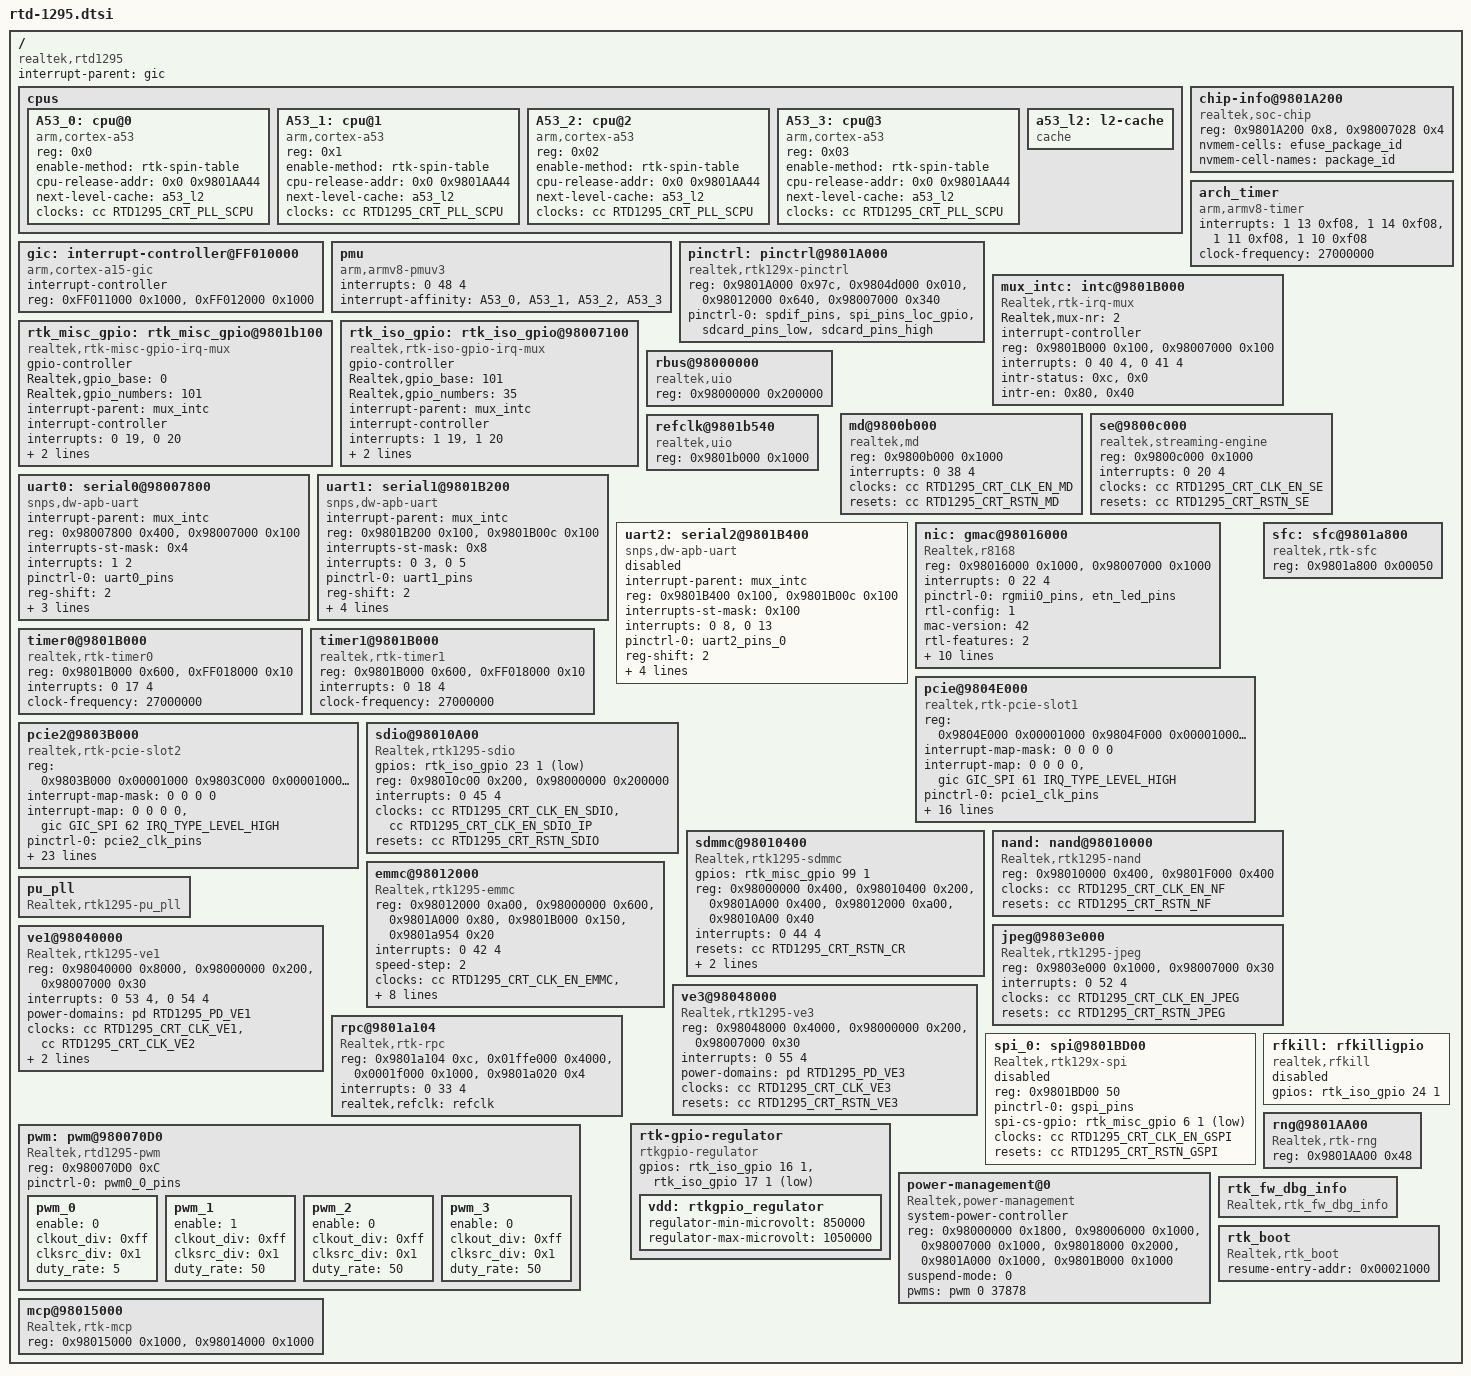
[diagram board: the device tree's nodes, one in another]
#include <dt-bindings/interrupt-controller/irq.h>
#include <dt-bindings/interrupt-controller/arm-gic.h>
#include "rtd-129x.dtsi"
/include/ "rtd-1295-pinctrl.dtsi"
/include/ "rtd-1295-usb.dtsi"
#include  "rtd-1295-sata.dtsi"
/include/ "rtd-129x-dcsys-debug.dtsi"

/{
	compatible = "realtek,rtd1295";
	interrupt-parent = <&gic>;
	#address-cells = <1>;
	#size-cells = <1>;

	cpus {
		#address-cells = <1>;
		#size-cells = <0>;

		A53_0: cpu@0 {
			device_type = "cpu";
			compatible = "arm,cortex-a53", "arm,armv8";
			reg = <0x0>;
			enable-method = "rtk-spin-table";
			cpu-release-addr = <0x0 0x9801AA44>;
			next-level-cache = <&a53_l2>;
			clocks = <&cc RTD1295_CRT_PLL_SCPU>;
			#cooling-cells = <2>;
		};

		A53_1: cpu@1 {
			device_type = "cpu";
			compatible = "arm,cortex-a53", "arm,armv8";
			reg = <0x1>;
			enable-method = "rtk-spin-table";
			cpu-release-addr = <0x0 0x9801AA44>;
			next-level-cache = <&a53_l2>;
			clocks = <&cc RTD1295_CRT_PLL_SCPU>;
			#cooling-cells = <2>;
		};

		A53_2: cpu@2 {
			device_type = "cpu";
			compatible = "arm,cortex-a53", "arm,armv8";
			reg = <0x02>;
			enable-method = "rtk-spin-table";
			cpu-release-addr = <0x0 0x9801AA44>;
			next-level-cache = <&a53_l2>;
			clocks = <&cc RTD1295_CRT_PLL_SCPU>;
			#cooling-cells = <2>;
		};

		A53_3: cpu@3 {
			device_type = "cpu";
			compatible = "arm,cortex-a53", "arm,armv8";
			reg = <0x03>;
			enable-method = "rtk-spin-table";
			cpu-release-addr = <0x0 0x9801AA44>;
			next-level-cache = <&a53_l2>;
			clocks = <&cc RTD1295_CRT_PLL_SCPU>;
			#cooling-cells = <2>;
		};

		a53_l2: l2-cache {
			compatible = "cache";
		};
	};

	chip-info@9801A200 {
		compatible = "realtek,soc-chip";
		reg = <0x9801A200 0x8>,
			<0x98007028 0x4>;
		nvmem-cells = <&efuse_package_id>;
		nvmem-cell-names = "package_id";
	};

	arch_timer {
		compatible = "arm,armv8-timer";
		interrupts = <1 13 0xf08>,
			<1 14 0xf08>,
			<1 11 0xf08>,
			<1 10 0xf08>;
		clock-frequency = <27000000>;
	};

	gic: interrupt-controller@FF010000 {
		compatible = "arm,cortex-a15-gic";
		#interrupt-cells = <3>;
		interrupt-controller;
		reg = <0xFF011000 0x1000>,
			<0xFF012000 0x1000>;
	};

	pmu {
		compatible = "arm,armv8-pmuv3";
		interrupts = <0 48 4>;
		interrupt-affinity = <&A53_0>,
			<&A53_1>,
			<&A53_2>,
			<&A53_3>;
	};

	pinctrl: pinctrl@9801A000 {
		compatible = "realtek,rtk129x-pinctrl";
		reg = <0x9801A000 0x97c>,
			<0x9804d000 0x010>,
			<0x98012000 0x640>,
			<0x98007000 0x340>;
		#gpio-range-cells = <3>;
		pinctrl-names = "default";
		pinctrl-0 =
			<&spdif_pins>,
			<&spi_pins_loc_gpio>,
			<&sdcard_pins_low>,
			<&sdcard_pins_high>;
		status = "okay";
	};

	mux_intc: intc@9801B000 {
		compatible = "Realtek,rtk-irq-mux";
		Realtek,mux-nr = <2>;
		#interrupt-cells = <2>;
		interrupt-controller;
		reg = <0x9801B000 0x100>, /* MISC_TOP MISC_ISO */
			<0x98007000 0x100>;
		interrupts = <0 40 4>, <0 41 4>;
		intr-status = <0xc>, <0x0>;
		intr-en = <0x80>, <0x40>;
		status = "okay";
	};

	rtk_misc_gpio: rtk_misc_gpio@9801b100 {
		compatible = "realtek,rtk-misc-gpio-irq-mux";
		gpio-controller;
		#gpio-cells = <3>; /*must be the same with gpiochip.of_gpio_n_cells*/
		Realtek,gpio_base = <0>;
		Realtek,gpio_numbers = <101>;
		interrupt-parent = <&mux_intc>;
		#interrupt-cells = <1>;
		interrupt-controller;
		interrupts = <0 19>, <0 20>; /*GPIOA_INT   GPIODA_INT*/
		reg = <0x9801b000 0x100>,
			<0x9801b100 0x100>; /* MISC_SYS MISC_GPIO*/
		gpio-ranges = <&pinctrl 0 0 101>;
		status = "okay";
	};

	rtk_iso_gpio: rtk_iso_gpio@98007100 {
		compatible = "realtek,rtk-iso-gpio-irq-mux";
		gpio-controller;
		#gpio-cells = <3>;
		Realtek,gpio_base = <101>;
		Realtek,gpio_numbers = <35>;
		interrupt-parent = <&mux_intc>;
		#interrupt-cells = <1>;
		interrupt-controller;
		interrupts = <1 19>, <1 20>; /*GPIOA_INT   GPIODA_INT*/
		reg = <0x98007000 0x100>,
			<0x98007100 0x100>; /* ISO_SYS ISO_GPIO*/
		gpio-ranges = <&pinctrl 0 101 35>;
		status = "okay";
	};

	rbus@98000000 {
		compatible = "realtek,uio";
		reg = <0x98000000 0x200000>;
		status = "okay";
	};

	md@9800b000 {
		compatible = "realtek,md";
		reg = <0x9800b000 0x1000>;
		interrupts = <0 38 4>; /* 70 - 32 = 38 */
		clocks = <&cc RTD1295_CRT_CLK_EN_MD>;
		resets = <&cc RTD1295_CRT_RSTN_MD>;
		status = "okay";
	};

	se@9800c000 {
		compatible = "realtek,streaming-engine";
		reg = <0x9800c000 0x1000>;
		interrupts = <0 20 4>; /* 52 - 32 = 20 */
		clocks = <&cc RTD1295_CRT_CLK_EN_SE>;
		resets = <&cc RTD1295_CRT_RSTN_SE>;
		status = "okay";
	};

	refclk@9801b540 {
		compatible = "realtek,uio";
		reg = <0x9801b000 0x1000>;
		status = "okay";
	};

	uart0: serial0@98007800 {
		compatible = "snps,dw-apb-uart";
		interrupt-parent = <&mux_intc>;
		reg = <0x98007800 0x400>,
			<0x98007000 0x100>;
		interrupts-st-mask = <0x4>;
		interrupts = <1 2>;
		pinctrl-names = "default";
		pinctrl-0 = <&uart0_pins>;
		reg-shift = <2>;
		reg-io-width = <4>;
		clock-names = "apb_pclk";
		clocks = <&ic RTD1295_ISO_CLK_EN_UR0>;
		clock-frequency = <27000000>; /* This value must be override by the board. */
		status = "okay";
	};

	uart1: serial1@9801B200 {
		compatible = "snps,dw-apb-uart";
		interrupt-parent = <&mux_intc>;
		reg = <0x9801B200 0x100>,
			<0x9801B00c 0x100>;
		interrupts-st-mask = <0x8>;
		interrupts = <0 3>, <0 5>; /*UR1_INT and UR1_TO_INT*/
		pinctrl-names = "default";
		pinctrl-0 = <&uart1_pins>;
		reg-shift = <2>;
		reg-io-width = <4>;
		clock-names = "apb_pclk";
		clocks = <&cc RTD1295_CRT_CLK_EN_UR1>;
		resets = <&cc RTD1295_CRT_RSTN_UR1>;
		/* This value must be overriden by the board. */
		clock-frequency = <0>;
		status = "okay";
	};

	uart2: serial2@9801B400 {
		compatible = "snps,dw-apb-uart";
		interrupt-parent = <&mux_intc>;
		reg = <0x9801B400 0x100>,
			<0x9801B00c 0x100>;
		interrupts-st-mask = <0x100>;
		interrupts = <0 8>, <0 13>; /*UR2_INT and UR2_TO_INT*/
		pinctrl-names = "default";
		pinctrl-0 = <&uart2_pins_0>;
		reg-shift = <2>;
		reg-io-width = <4>;
		clock-names = "apb_pclk";
		clocks = <&cc RTD1295_CRT_CLK_EN_UR2>;
		resets = <&cc RTD1295_CRT_RSTN_UR2>;
		/* This value must be overriden by the board. */
		clock-frequency = <0>;
		status = "disabled"; /* Disable UR2 fic since we don't use it now */
	};

	nic: gmac@98016000 {
		compatible = "Realtek,r8168";
		reg = <0x98016000 0x1000>,
			<0x98007000 0x1000>;
		interrupts = <0 22 4>;
		pinctrl-names = "default";
		pinctrl-0 = <&rgmii0_pins>,
			<&etn_led_pins>;
		rtl-config = <1>;
		mac-version = <42>; /* RTL_GIGA_MAC_VER_42 */
		rtl-features = <2>; /* BIT(2) GMii */
		output-mode = <0>; /* 0:embedded PHY, 1:RGMII to MAC, 2:RGMII to PHY */
		rgmii-voltage = <1>; /* 1:1.8V, 2: 2.5V, 3:3.3V */
		rgmii-tx-delay = <0>; /* 0: 0ns, 1: 2ns */
		rgmii-rx-delay = <0>; /* 0: 0ns, 1: 2ns */
		ext-phy-id = <1>; /* 0 ~ 31, only valid when output-mode = 2 */
		eee = <1>; /* KDP-1095: Enable Energy efficient Ethernet */
		clocks = <&ic RTD1295_ISO_CLK_EN_ETN_250M>,
			<&ic RTD1295_ISO_CLK_EN_ETN_SYS>;
		clock-names = "etn_250m",
			"etn_sys";
		resets = <&ic RTD1295_ISO_RSTN_GMAC>,
			<&ic RTD1295_ISO_RSTN_GPHY>;
		reset-names = "gmac",
			"gphy";
		status = "okay";
	};

	timer0@9801B000 {
		compatible = "realtek,rtk-timer0";
		reg = <0x9801B000 0x600>,
			<0xFF018000 0x10>;
		interrupts = <0 17 4>;
		clock-frequency = <27000000>;
		status = "okay";
	};

	timer1@9801B000 {
		compatible = "realtek,rtk-timer1";
		reg = <0x9801B000 0x600>,
			<0xFF018000 0x10>;
		interrupts = <0 18 4>;
		clock-frequency = <27000000>;
		status = "okay";
	};

	pcie@9804E000 {
		compatible = "realtek,rtk-pcie-slot1";
		reg = <0x9804E000 0x00001000
			0x9804F000 0x00001000
			0x9801C600 0x00000100
			0x9801A000 0x00000300
			0x98012000 0x00001000>;
		interrupt-names = "rtk-pcie1-intr";
		#interrupt-cells = <1>;
		interrupt-map-mask = <0 0 0 0>;
		interrupt-map = <0 0 0 0 &gic GIC_SPI 61 IRQ_TYPE_LEVEL_HIGH>;
		pinctrl-names = "default";
		pinctrl-0 = <&pcie1_clk_pins>;
		bus-range = <0x00 0xff>;
		linux,pci-domain = <0>;
		device_type = "pci";
		gpios = <&rtk_misc_gpio 18 1 0 >;
		#size-cells = <2>;
		#address-cells = <3>;
		num-lanes = <1>;
		ranges = <0x02000000 0x00000000 0xC0000000  0xC0000000 0x00000000 0x01000000
			0x01000000 0x00000000 0x00030000  0x00030000 0x00000000 0x00010000>;
		resets = <&cc RTD1295_CRT_RSTN_PCIE0>,
			<&cc RTD1295_CRT_RSTN_PCIE0_CORE>,
			<&cc RTD1295_CRT_RSTN_PCIE0_POWER>,
			<&cc RTD1295_CRT_RSTN_PCIE0_NONSTITCH>,
			<&cc RTD1295_CRT_RSTN_PCIE0_STITCH>,
			<&cc RTD1295_CRT_RSTN_PCIE0_PHY>,
			<&cc RTD1295_CRT_RSTN_PCIE0_PHY_MDIO>;
		reset-names = "rstn",
			"core",
			"power",
			"nonstitch",
			"stitch",
			"phy",
			"phy_mdio";
		clocks = <&cc RTD1295_CRT_CLK_EN_PCIE0>;
		debug-mode = <0>;
		status = "okay";
		phys_a = <0x31810801>,
			<0xB2001101>,
			<0x00100001>;
		phys_b = <0x00000003>,
			<0x00900001>,
			<0x40080401>,
			<0x5AC10801>,
			<0x32b40f01>,
			<0x72001101>;
	};

	pcie2@9803B000 {
		compatible = "realtek,rtk-pcie-slot2";
		reg = <0x9803B000 0x00001000
			0x9803C000 0x00001000
			0x9801C600 0x00000100
			0x9801A000 0x00000300
			0x98012000 0x00001000>;
		interrupt-names = "rtk-pcie2-intr";
		#interrupt-cells = <1>;
		interrupt-map-mask = <0 0 0 0>;
		interrupt-map = <0 0 0 0 &gic GIC_SPI 62 IRQ_TYPE_LEVEL_HIGH>;
		pinctrl-names = "default";
		pinctrl-0 = <&pcie2_clk_pins>;
		bus-range = <0x00 0xff>;
		linux,pci-domain = <1>;
		device_type = "pci";
		gpios = <&rtk_misc_gpio 20 1 0>;
		#size-cells = <2>;
		#address-cells = <3>;
		num-lanes = <1>;
		ranges = <0x02000000 0x00000000 0xC1000000  0xC1000000 0x00000000 0x01000000
			0x01000000 0x00000000 0x00040000  0x00040000 0x00000000 0x00010000>;
		speed-mode = <0>; // 0:GEN1, 1:GEN2
		debug-mode = <0>;
		resets = <&cc RTD1295_CRT_RSTN_PCIE1>,
			<&cc RTD1295_CRT_RSTN_PCIE1_CORE>,
			<&cc RTD1295_CRT_RSTN_PCIE1_POWER>,
			<&cc RTD1295_CRT_RSTN_PCIE1_NONSTITCH>,
			<&cc RTD1295_CRT_RSTN_PCIE1_STITCH>,
			<&cc RTD1295_CRT_RSTN_PCIE1_PHY>,
			<&cc RTD1295_CRT_RSTN_PCIE1_PHY_MDIO>;
		reset-names = "rstn",
			"core",
			"power",
			"nonstitch",
			"stitch",
			"phy",
			"phy_mdio";
		clocks = <&cc RTD1295_CRT_CLK_EN_PCIE1>;
		status = "okay";
		phys = <0x00000003>, /* #Write soft reset */
			<0x27E90301>,
			<0x52F50401>, /* #F code,close SSC */
			<0xead70501>, /* #modify N code */
			<0x000c0601>, /* #modify CMU ICP(TX jitter) */
			<0xa6530a01>, /* #modify CMU RS(tx jitter) */
			<0xC4662001>, /* #modify AMP */
			<0x8EA01B01>,
			<0x8EA05B01>,
			<0xa84a0101>, /* #modify Rx parameter */
			<0xb8032b01>, /* #clk driving */
			<0x27e94301>, /* #EQ */
			<0x52f54401>, /* #F code,close SSC */
			<0xead74501>, /* #modify N code */
			<0x000c4601>, /* #modify CMU ICP(TX jitter) */
			<0xa6534a01>, /* #modify CMU RS(tx jitter) */
			<0xd4776001>, /* #modify AMP */
			<0xa84a4101>, /* #modify Rx parameter */
			<0xa8036b01>, /* #clk driving */
			<0x01225a01>,
			<0x521C0901>, /* #for calibration bit[9]=1" */
			<0x501C0901>, /* #for calibration bit[9]=0" */
			<0x521C0901>, /* #for calibration bit[9]=1" */
			<0x08282401>,
			<0x08286401>;
	};

	sfc: sfc@9801a800 {
                compatible = "realtek,rtk-sfc";
                reg = <0x9801a800 0x00050>;
                status = "okay";
        };

	sdio@98010A00 {
		compatible = "Realtek,rtk1295-sdio";
		gpios = <&rtk_iso_gpio 23 1 1>;
		reg = <0x98010c00 0x200>,
			<0x98000000 0x200000>;
		interrupts = <0 45 4>;
		clocks = <&cc RTD1295_CRT_CLK_EN_SDIO>,
			<&cc RTD1295_CRT_CLK_EN_SDIO_IP>;
		clock-names = "sdio",
			"sdio_ip";
		resets = <&cc RTD1295_CRT_RSTN_SDIO>;
		status = "okay";
	};

	sdmmc@98010400 {
		compatible = "Realtek,rtk1295-sdmmc";
		gpios = <&rtk_misc_gpio 99 1 0>; /*sd power , output, default high  (poweroff) */
		reg = <0x98000000 0x400>, /* CRT */
			<0x98010400 0x200>, /* SDMMC */
			<0x9801A000 0x400>, /* BS2 */
			<0x98012000 0xa00>, /* EMMC */
			<0x98010A00 0x40>; /* SDIO */
		interrupts = <0 44 4>;
		/*pinctrl-names = "default";
		pinctrl-0 = <&sdcard_pins_low>,
			<&sdcard_pins_high>;*/
		resets = <&cc RTD1295_CRT_RSTN_CR>;
		clocks = <&cc RTD1295_CRT_CLK_EN_CR>,
			<&cc RTD1295_CRT_CLK_EN_SD_IP>;
		clock-names = "cr",
			"sd_ip";
		status = "okay";
	};

	nand: nand@98010000 {
		compatible = "Realtek,rtk1295-nand";
		reg = <0x98010000 0x400>, /* NWC */
			<0x9801F000 0x400>; /* SWC */
		clocks = <&cc RTD1295_CRT_CLK_EN_NF>;
		resets = <&cc RTD1295_CRT_RSTN_NF>;
		status = "okay";
	};

	emmc@98012000 {
		compatible = "Realtek,rtk1295-emmc";
		reg = <0x98012000 0xa00>, /*EMMC*/
			<0x98000000 0x600>, /*CRT */
			<0x9801A000 0x80>, /*SB2*/
			<0x9801B000 0x150>, /*MISC*/
			<0x9801a954 0x20>;  /*SB2_DBG*/
		interrupts = <0 42 4>;
		speed-step = <2>; /* 0: sdr50, 1: ddr50, 2: hs200, 3: hs400 */
		clocks = <&cc RTD1295_CRT_CLK_EN_EMMC>,
			<&cc RTD1295_CRT_CLK_EN_EMMC_IP>,
			<&cc RTD1295_CRT_CLK_EN_CR>;
		clock-names = "emmc",
			"emmc_ip",
			"cr";
		resets = <&cc RTD1295_CRT_RSTN_EMMC>;
		reset-names = "emmc";
		status = "okay";
		pddrive_nf_s0 = <1 0x77 0x77 0x77 0x33>; /* pddrive_nf0, pddrive_nf1, pddrive_nf2, pddrive_nf3, pddrive_nf4 ; for sdr50 */
		pddrive_nf_s2 = <1 0xbb 0xbb 0xbb 0x33>; /* pddrive_nf0, pddrive_nf1, pddrive_nf2, pddrive_nf3, pddrive_nf4 ; for hs200 */
		pddrive_nf_s3 = <1 0xff 0x99 0xaa 0x33>; /* pddrive_nf0, pddrive_nf1, pddrive_nf2, pddrive_nf3, pddrive_nf4 ; for hs400 */
		phase_tuning = <0 0>; /* arg0: tx tuning switch, arg1: rx tuning switch*/
		dqs_tuning = <1>;
	};

	pu_pll {
		compatible = "Realtek,rtk1295-pu_pll";
	};

	jpeg@9803e000 {
		compatible = "Realtek,rtk1295-jpeg";
		reg = <0x9803e000 0x1000>,
			<0x98007000 0x30>;
		interrupts = <0 52 4>;
		clocks = <&cc RTD1295_CRT_CLK_EN_JPEG>;
		clock-names = "jpeg";
		resets = <&cc RTD1295_CRT_RSTN_JPEG>;
		status = "okay";
	};

	ve1@98040000 {
		compatible = "Realtek,rtk1295-ve1";
		reg = <0x98040000 0x8000>,
			<0x98000000 0x200>,
			<0x98007000 0x30>;
		interrupts = <0 53 4>, <0 54 4>;
		power-domains = <&pd RTD1295_PD_VE1>;
		clocks = <&cc RTD1295_CRT_CLK_VE1>,
			<&cc RTD1295_CRT_CLK_VE2>;
		clock-names = "clk_ve1",
			"clk_ve2";
		resets = <&cc RTD1295_CRT_RSTN_VE1>,
			<&cc RTD1295_CRT_RSTN_VE2>;
		reset-names = "ve1",
			"ve2";
		status = "okay";
	};

	ve3@98048000 {
		compatible = "Realtek,rtk1295-ve3";
		reg = <0x98048000 0x4000>,
			<0x98000000 0x200>,
			<0x98007000 0x30>;
		interrupts = <0 55 4>;
		power-domains = <&pd RTD1295_PD_VE3>;
		clocks = <&cc RTD1295_CRT_CLK_VE3>;
		resets = <&cc RTD1295_CRT_RSTN_VE3>;
		status = "okay";
	};

	rpc@9801a104 {
		compatible = "Realtek,rtk-rpc";
		reg = <0x9801a104 0xc>, /* rpc intr en */
			<0x01ffe000 0x4000>, /* rpc ring buffer */
			<0x0001f000 0x1000>, /* rpc common */
			<0x9801a020 0x4>; /* rbus sync */
		interrupts = <0 33 4>;
		realtek,refclk = <&refclk>;
		status = "okay";
	};

	spi_0: spi@9801BD00 {
		compatible = "Realtek,rtk129x-spi";
		reg = <0x9801BD00 50>;
		pinctrl-names = "default";
		pinctrl-0 = <&gspi_pins>;
		spi-cs-gpio = <&rtk_misc_gpio 6 1 1>;
		clocks = <&cc RTD1295_CRT_CLK_EN_GSPI>;
		resets = <&cc RTD1295_CRT_RSTN_GSPI>;
		status = "disabled";
	};

	pwm: pwm@980070D0 {
		compatible = "Realtek,rtd1295-pwm";
		#pwm-cells = <2>;
		reg = <0x980070D0 0xC>;
		pinctrl-names = "default";
		pinctrl-0 = <&pwm0_0_pins>;
		status = "okay";
		pwm_0 {
			enable = <0>;
			clkout_div = <0xff>; //default OCD: from 0x0 to 0xff
			clksrc_div = <0x1>; //default OSD: from 0x0 to 0xf
			duty_rate = <5>; //default duty_rate 0 ~ 100
		};
		pwm_1 {
			enable = <1>;
			clkout_div = <0xff>; //default OCD: from 0x0 to 0xff
			clksrc_div = <0x1>; //default OSD: from 0x0 to 0xf
			duty_rate = <50>; //default duty_rate 0 ~ 100
		};
		pwm_2 {
			enable = <0>;
			clkout_div = <0xff>; //default OCD: from 0x0 to 0xff
			clksrc_div = <0x1>; //default OSD: from 0x0 to 0xf
			duty_rate = <50>; //default duty_rate 0 ~ 100
		};
		pwm_3 {
			enable = <0>;
			clkout_div = <0xff>; //default OCD: from 0x0 to 0xff
			clksrc_div = <0x1>; //default OSD: from 0x0 to 0xf
			duty_rate = <50>; //default duty_rate 0 ~ 100
		};
	};

	rfkill: rfkilligpio {
		compatible = "realtek,rfkill";
		gpios = <&rtk_iso_gpio 24 1 0>; /*bt power , output, default low */
		status = "disabled";
	};

	rtk-gpio-regulator {
		compatible = "rtkgpio-regulator";
		gpios = <&rtk_iso_gpio 16 1 0>, <&rtk_iso_gpio 17 1 1>;
		//status = "disabled";
		status = "okay";
		vdd: rtkgpio_regulator {
			regulator-min-microvolt = <850000>;
			regulator-max-microvolt = <1050000>;
		};
	};

	power-management@0 {
		compatible = "Realtek,power-management";
		system-power-controller;
		reg = <0x98000000 0x1800>, /* CRT */
			<0x98006000 0x1000>, /* AIO */
			<0x98007000 0x1000>, /* ISO */
			<0x98018000 0x2000>, /* TVE */
			<0x9801A000 0x1000>, /* SB2 */
			<0x9801B000 0x1000>; /* MISC */
		suspend-mode = <0>; // 0:SUSPEND_TO_RAM, 1:SUSPEND_TO_COOLBOOT, 2:SUSPEND_TO_WFI
		pwms = <&pwm 0 37878>;
		status = "okay";
	};

	rng@9801AA00 {
		compatible = "Realtek,rtk-rng";
		reg = <0x9801AA00 0x48>;
	};

	mcp@98015000 {
		compatible = "Realtek,rtk-mcp";
		reg = <0x98015000 0x1000>,
			<0x98014000 0x1000>;
		status = "okay";
	};

	rtk_fw_dbg_info {
		compatible = "Realtek,rtk_fw_dbg_info";
		status = "okay";
	};

	rtk_boot {
		compatible = "Realtek,rtk_boot";
		resume-entry-addr = <0x00021000>;
		status = "okay";
	};
};

